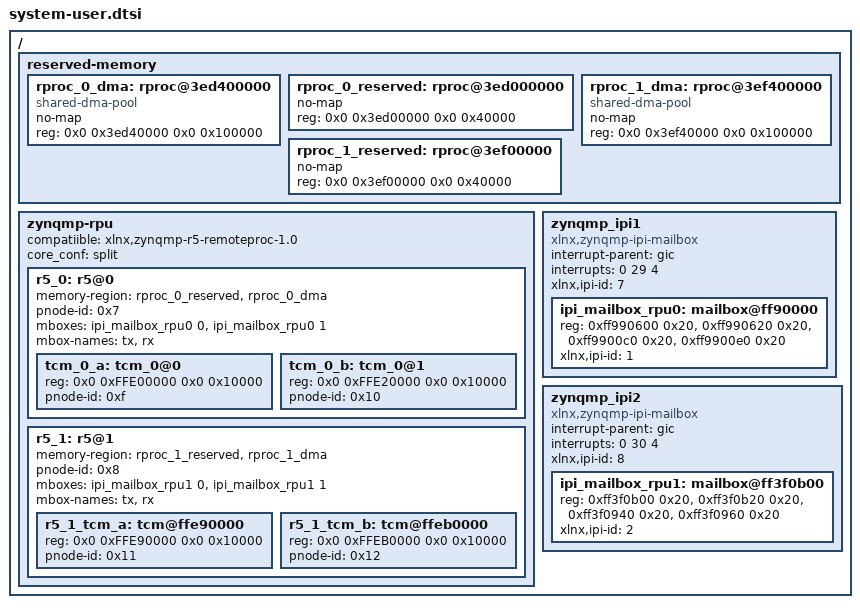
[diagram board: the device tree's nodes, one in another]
/ {
	reserved-memory {
		#address-cells = <2>;
		#size-cells = <2>;
		ranges;
		rproc_0_dma: rproc@3ed400000 {
			no-map;
			compatible = "shared-dma-pool";
			reg = <0x0 0x3ed40000 0x0 0x100000>;
		};
		rproc_0_reserved: rproc@3ed000000 {
			no-map;
			reg = <0x0 0x3ed00000 0x0 0x40000>;
		};
		rproc_1_dma: rproc@3ef400000 {
				no-map;
				compatible = "shared-dma-pool";
				reg = <0x0 0x3ef40000 0x0 0x100000>;
			};
		rproc_1_reserved: rproc@3ef00000 {
				no-map;
				reg = <0x0 0x3ef00000 0x0 0x40000>;
		};
	};
	zynqmp-rpu {
		compatiible = "xlnx,zynqmp-r5-remoteproc-1.0";
		#address-cells = <2>;
		#size-cells = <2>;
		ranges;
		core_conf = "split";
		r5_0: r5@0 {
			#address-cells = <2>;
			#size-cells = <2>;
			ranges;
			memory-region = <&rproc_0_reserved>, <&rproc_0_dma>;
			pnode-id = <0x7>;
			mboxes = <&ipi_mailbox_rpu0 0>, <&ipi_mailbox_rpu0 1>;
			mbox-names = "tx", "rx";
			tcm_0_a: tcm_0@0 {
				reg = <0x0 0xFFE00000 0x0 0x10000>;
				pnode-id = <0xf>;
			};
			tcm_0_b: tcm_0@1 {
				reg = <0x0 0xFFE20000 0x0 0x10000>;
				pnode-id = <0x10>;
			};
		};
		r5_1: r5@1 {
		    #address-cells = <2>;
		    #size-cells = <2>;
		    ranges;
		    memory-region = <&rproc_1_reserved>, <&rproc_1_dma>;
		    pnode-id = <0x8>;
		    mboxes = <&ipi_mailbox_rpu1 0>, <&ipi_mailbox_rpu1 1>;
		    mbox-names = "tx", "rx";
		    r5_1_tcm_a: tcm@ffe90000 {
			reg = <0x0 0xFFE90000 0x0 0x10000>;
			pnode-id = <0x11>;
		    };
		    r5_1_tcm_b: tcm@ffeb0000 {
			reg = <0x0 0xFFEB0000 0x0 0x10000>;
			pnode-id = <0x12>;
		    };
		};
	};


	zynqmp_ipi1 {
		compatible = "xlnx,zynqmp-ipi-mailbox";
		interrupt-parent = <&gic>;
		interrupts = <0 29 4>;
		xlnx,ipi-id = <7>;
		#address-cells = <1>;
		#size-cells = <1>;
		ranges;

		/* APU<->RPU0 IPI mailbox controller */
		ipi_mailbox_rpu0: mailbox@ff90000 {
			reg = <0xff990600 0x20>,
			      <0xff990620 0x20>,
			      <0xff9900c0 0x20>,
			      <0xff9900e0 0x20>;
			reg-names = "local_request_region",
				    "local_response_region",
				    "remote_request_region",
				    "remote_response_region";
			#mbox-cells = <1>;
			xlnx,ipi-id = <1>;
		};
	};
	zynqmp_ipi2 {
        compatible = "xlnx,zynqmp-ipi-mailbox";
        interrupt-parent = <&gic>;
        interrupts = <0 30 4>;
        xlnx,ipi-id = <8>;
        #address-cells = <1>;
        #size-cells = <1>;
        ranges;
        /* APU<->RPU1 IPI mailbox controller */
        ipi_mailbox_rpu1: mailbox@ff3f0b00 {
            reg = <0xff3f0b00 0x20>,
                  <0xff3f0b20 0x20>,
                  <0xff3f0940 0x20>,
                  <0xff3f0960 0x20>;
            reg-names = "local_request_region",
                    "local_response_region",
                    "remote_request_region",
                    "remote_response_region";
            #mbox-cells = <1>;
            xlnx,ipi-id = <2>;
        };
    };
};
